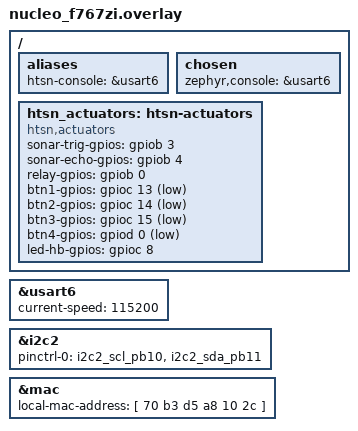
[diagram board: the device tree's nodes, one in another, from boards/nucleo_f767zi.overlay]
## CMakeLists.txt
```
# htsn-tsn endpoint (STM32 Nucleo-F767ZI) — Zephyr build.
#
# Replaces the previous STM32CubeIDE / FreeRTOS / lwIP CMake build (see git
# history). Build + flash with west (a Zephyr SDK is required; see README
# "Building & flashing"):
#
#   cd stm32-tsn
#   west build -b nucleo_f767zi .
#   west flash -r          # on-board ST-Link (or: west flash --runner openocd)
#
# The app's source tree is unchanged from the FreeRTOS build in *layout*; the
# C files use the Zephyr kernel / device model instead of FreeRTOS + STM32 HAL.
cmake_minimum_required(VERSION 3.20.0)

find_package(Zephyr REQUIRED HINTS $ENV{ZEPHYR_BASE})
project(htsn_tsn C ASM)

target_sources(app PRIVATE
  src/main.c
  Board/board.c
  Board/pwm.c
  tsn/ptp.c
  tsn/htsn_clock.c
  tsn/eth_proto.c
  actuators/htsn_sonar.c
  actuators/htsn_display.c
  actuators/htsn_actuator.c)

target_include_directories(app PRIVATE
  inc
  Board
  tsn
  actuators)
```

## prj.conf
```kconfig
# htsn-tsn endpoint (Zephyr) — Nucleo-F767ZI
CONFIG_COMPILER_OPT="-Os"

# ---- Threads ----
CONFIG_MAIN_STACK_SIZE=2048
CONFIG_SYSTEM_WORKQUEUE_STACK_SIZE=4096
CONFIG_INIT_STACKS=y
CONFIG_HEAP_MEM_POOL_SIZE=8192

# ---- Real-time preemption (gPTP timing) ----
# The Zephyr 4.5 kernel is fully preemptable by default (CONFIG_PREEMPT_ENABLED);
# there is no more CONFIG_PREEMPT symbol to set. Make the net I/O threads
# preemptive too, so an inbound Sync frame is handed to the socket (and the PTP
# thread's select() wakes) promptly, cutting T3 jitter. The RX thread runs at
# prio 2, the TX threads around prio 7; the PTP thread is raised to prio 4
# (tsn/ptp.c) so it sits above the TX/flow/cmd threads but below the RX thread
# and heartbeat.
CONFIG_NET_TC_THREAD_PREEMPTIVE=y
CONFIG_ETH_STM32_HAL_RX_THREAD_PREEMPTIVE=y

# ---- Console: printf (LOGI/LOGW/LOGE) -> USART6 (the NUCLEO ST-Link VCP) ----
CONFIG_SERIAL=y
CONFIG_CONSOLE=y
CONFIG_UART_CONSOLE=y
CONFIG_LOG=n

# ---- Networking: Zephyr net stack + POSIX sockets (replaces lwIP) ----
CONFIG_NETWORKING=y
CONFIG_POSIX_API=y
CONFIG_POSIX_NETWORKING=y
CONFIG_NET_IPV4=y
CONFIG_NET_IPV6=n
CONFIG_NET_SOCKETS=y
CONFIG_NET_UDP=y
CONFIG_NET_TCP=n
# IPv4 multicast (gPTP slave joins 224.0.1.129, see tsn/ptp.c) is enabled by
# CONFIG_NET_IPV4=y above; Zephyr 4.5 has no separate multicast Kconfig symbol.
# AF_PACKET raw socket: used to emit 802.1Q-tagged telemetry egress (VLAN/PCP)
# once a TSN config with vlan_id>0 is applied. See tsn/eth_proto.c.
CONFIG_NET_SOCKETS_PACKET=y
# IGMPv2: required for setsockopt(IP_ADD_MEMBERSHIP) in tsn/ptp.c to actually
# join the PTP multicast group (224.0.1.129). Without it net_ipv4_igmp_join is
# compiled out and the join returns -ENOSYS, so the IPv4 layer drops the GM's
# multicast Sync/Follow_Up and the clock never locks. Selects NET_IPV4_HDR_OPTIONS.
CONFIG_NET_IPV4_IGMP=y
# Promiscuous mode: the STM32 DWc MAC driver cannot program its hardware
# multicast filter (no ETHERNET_FILTER_TYPE_DST_MAC_ADDRESS), so even with a
# successful IGMP join the NIC would drop the 224.0.1.129 frames at L2. Promisc
# lets the NIC pass them to the stack; the IGMP join above then accepts them at
# L3 and the UDP socket receives the Sync/Follow_Up/Delay_Resp.
CONFIG_NET_PROMISCUOUS_MODE=y
CONFIG_NET_IPV4_AUTO=y
CONFIG_NET_CONFIG_INIT_TIMEOUT=10
CONFIG_NET_DEFAULT_IF_ETHERNET=y

# Static L3 config (no DHCP): the endpoint is 192.168.1.20, the RPi/CNC is
# 192.168.1.10. The PTP + UDP control/telemetry link both ride this.
CONFIG_NET_CONFIG_SETTINGS=y
CONFIG_NET_CONFIG_PEER_IPV4_ADDR="192.168.1.10"
CONFIG_NET_CONFIG_MY_IPV4_ADDR="192.168.1.20"
CONFIG_NET_CONFIG_MY_IPV4_NETMASK="255.255.255.0"
CONFIG_NET_DHCPV4=n

# ---- Ethernet: STM32 MAC + the on-board LAN8742A PHY ----
# (auto-selected from the &ethernet node in the overlay; the PHY comes from the
# board DTS. If your Zephyr version names the driver differently, set the
# matching symbol here — see README "First build".)
CONFIG_ETH_STM32_HAL=y
CONFIG_NET_ARP_TABLE_SIZE=4
CONFIG_NET_SHELL=n

# ---- Net buffers / connections ----
# Headroom for IPv4 multicast delivery (net_conn_input clones the datagram per
# matching socket) plus the PTP, command and tagged-egress sockets, and enable
# the STM32 HAL receive filter so the 224.0.1.129 group is accepted.
CONFIG_NET_BUF_RX_COUNT=96
CONFIG_NET_BUF_TX_COUNT=48
CONFIG_NET_PKT_RX_COUNT=32
CONFIG_NET_PKT_TX_COUNT=32
CONFIG_NET_MAX_CONN=16
CONFIG_NET_MAX_CONTEXTS=16
CONFIG_ETH_STM32_MULTICAST_FILTER=y
CONFIG_NET_L2_ETHERNET_MCAST_FILTER_COUNT=4

# ---- PWM: servo (SG90) + buzzer, driven by Board/pwm.c (CMSIS shim) ----
CONFIG_PWM=y

# ---- I2C: SSD1306 OLED ----
CONFIG_I2C=y

# ---- GPIO: sonar, relay, buttons, heartbeat LED ----
CONFIG_GPIO=y
```

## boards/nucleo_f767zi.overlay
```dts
/* htsn-tsn endpoint peripheral overlay — Nucleo-F767ZI (Zephyr).
 *
 * The board DTS (boards/st/nucleo_f7/nucleo_f767zi.dts) provides the base
 * (UART, I2C2, the Ethernet MAC + LAN8742A PHY, GPIO controllers, timers).
 * This overlay (1) points the console at USART6, (2) enables the I2C2 OLED
 * bus and the Ethernet MAC with the endpoint MAC, and (3) declares the
 * actuator pins — the single source of truth for the physical wiring.
 *
 * RESERVED (on-board LAN8742A PHY): PA1/PA2/PA7/PC1/PC4/PC5 — do not reuse.
 *
 * The servo (PA8/TIM1_CH1) and buzzer (PB1/TIM3_CH4) PWM outputs are NOT
 * declared here: they are programmed directly in Board/pwm.c (a CMSIS shim),
 * which keeps the port independent of the version-fragile STM32 PWM binding.
 */
#include <dt-bindings/gpio/gpio.h>

/ {
	aliases {
		htsn-console = &usart6;
	};
	chosen {
		zephyr,console = &usart6;
	};

	/* Logical actuator wiring. C code reads these via GPIO_DT_SPEC_GET(). */
	htsn_actuators: htsn-actuators {
		compatible = "htsn,actuators";

		/* HC-SR04 sonar */
		sonar-trig-gpios = <&gpiob 3 GPIO_ACTIVE_HIGH>;
		sonar-echo-gpios = <&gpiob 4 GPIO_ACTIVE_HIGH>;

		/* Relay (drive high to energise) */
		relay-gpios      = <&gpiob 0 GPIO_ACTIVE_HIGH>;

		/* 4 push-buttons (active low, internal pull-up) */
		btn1-gpios = <&gpioc 13 (GPIO_ACTIVE_LOW | GPIO_PULL_UP)>;
		btn2-gpios = <&gpioc 14 (GPIO_ACTIVE_LOW | GPIO_PULL_UP)>;
		btn3-gpios = <&gpioc 15 (GPIO_ACTIVE_LOW | GPIO_PULL_UP)>;
		btn4-gpios = <&gpiod 0  (GPIO_ACTIVE_LOW | GPIO_PULL_UP)>;

		/* On-board heartbeat LED (LD1, PC8) */
		led-hb-gpios   = <&gpioc 8 GPIO_ACTIVE_HIGH>;
	};
};

/* ---- console: USART6 at 115200 (ST-Link VCP) ---- */
&usart6 {
	status = "okay";
	current-speed = <115200>;
};

/* ---- I2C2: SSD1306 OLED (PB10/PB11) ---- */
&i2c2 {
	status = "okay";
	pinctrl-0 = <&i2c2_scl_pb10 &i2c2_sda_pb11>;
	pinctrl-names = "default";
};

/* ---- Ethernet MAC: the on-board LAN8742A (PHY handled by the board DTS) ---- */
&mac {
	status = "okay";
	local-mac-address = [ 70 b3 d5 a8 10 2c ];
};
```

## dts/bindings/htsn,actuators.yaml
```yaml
description: HTSN TSN endpoint actuator pins

compatible: "htsn,actuators"

properties:
  sonar-trig-gpios:
    type: phandle-array
    description: HC-SR04 sonar trigger pin

  sonar-echo-gpios:
    type: phandle-array
    description: HC-SR04 sonar echo pin

  relay-gpios:
    type: phandle-array
    description: Relay control pin

  btn1-gpios:
    type: phandle-array
    description: Button 1

  btn2-gpios:
    type: phandle-array
    description: Button 2

  btn3-gpios:
    type: phandle-array
    description: Button 3

  btn4-gpios:
    type: phandle-array
    description: Button 4

  led-hb-gpios:
    type: phandle-array
    description: Heartbeat LED
```

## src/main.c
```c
/* htsn-tsn endpoint application (STM32F767ZI) — Zephyr.
 *
 * The RPi (CNC) is the peer: it is the PTP v2 grandmaster (ptpd), TSN
 * controller, OPC UA server, MQTT broker and the GUI. The PC is NOT a runtime
 * node.
 *
 * Zephyr (device model + DT overlay) brings up clocks, the USART6 console,
 * I2C2 and the Ethernet MAC before main() runs. This file is the application
 * layer on top of that: it starts the actuator PWM, the transport, PTP, and
 * the display/heartbeat threads.
 */
#include <zephyr/kernel.h>
#include "stm32f7xx.h"

#include "htsn_config.h"
#include "htsn_port.h"
#include "htsn_net.h"
#include "ptp.h"
#include "board.h"
#include "pwm.h"
#include "htsn_sonar.h"
#include "htsn_display.h"
#include "htsn_actuator.h"

#include <string.h>
#include <stdlib.h>

/* Command handler: the RPi CNC sends short verbs over the TSN link. */
static void on_command(const char *cmd, const char *arg, void *ud)
{
	(void)ud;
	if (!cmd) return;
	if (strcmp(cmd, "servo") == 0)       htsn_sonar_set_angle(atoi(arg));
	else if (strcmp(cmd, "sonar") == 0)  htsn_sonar_trigger();
	else if (strcmp(cmd, "relay") == 0)  htsn_actuator_relay(atoi(arg));
	else if (strcmp(cmd, "beep") == 0)   htsn_actuator_beep(atoi(arg));
	else if (strcmp(cmd, "hud") == 0)    htsn_display_on_telemetry(arg);
	else if (strcmp(cmd, "reboot") == 0) htsn_reset();
	else LOGW("unknown command '%s'\n", cmd);
}

static void on_button(int n, void *ud)
{
	(void)ud;
	LOGI("button %d pressed\n", n);
	/* buttons publish their state via htsn_display_tick(); a press can also
	 * trigger a sonar sweep, matching the esp32-02 behaviour. */
	htsn_sonar_trigger();
}

/* ---- display + heartbeat threads (started from main after init) ---- */
K_THREAD_STACK_DEFINE(display_stack, 4096);
K_THREAD_STACK_DEFINE(heartbeat_stack, 1024);
static struct k_thread display_thread, heartbeat_thread;

static void display_task_fn(void *a, void *b, void *c)
{
	(void)a; (void)b; (void)c;
	for (;;) {
		htsn_display_tick();
		k_msleep(100);
	}
}

static void heartbeat_task_fn(void *a, void *b, void *c)
{
	(void)a; (void)b; (void)c;
	for (;;) {
		board_heartbeat_toggle();
		k_msleep(1000);
	}
}

int main(void)
{
	board_dwt_init();
	board_heartbeat_init();
	htsn_pwm_init();               /* servo + buzzer (CMSIS shim) */

	htsn_display_set_btn_cb(on_button, NULL);
	htsn_net_set_cmd_cb(on_command, NULL);
	if (htsn_net_init() != 0)
		LOGE("net init failed — is the Ethernet link to the RPi CNC up?\n");
	htsn_ptp_init();

	htsn_sonar_init(HTSN_NODE_ID);
	htsn_display_init(HTSN_NODE_ID);   /* blocks ~0.5 s probing the OLED */
	htsn_actuator_init(HTSN_NODE_ID);

	k_thread_create(&display_thread, display_stack, K_THREAD_STACK_SIZEOF(display_stack),
	                display_task_fn, NULL, NULL, NULL, 4, 0, K_NO_WAIT);
	k_thread_create(&heartbeat_thread, heartbeat_stack, K_THREAD_STACK_SIZEOF(heartbeat_stack),
	                heartbeat_task_fn, NULL, NULL, NULL, 3, 0, K_NO_WAIT);

	LOGI("htsn-tsn endpoint %s up (CNC = %s)\n", HTSN_NODE_ID, CNC_IP);
	return 0;   /* main thread done; the other threads keep running */
}
```

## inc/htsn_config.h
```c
/* htsn-tsn node configuration: identity, network endpoints, timings. */
#ifndef HTSN_CONFIG_H
#define HTSN_CONFIG_H

/* Node identity (shown in the GUI and in every telemetry frame). */
#ifndef HTSN_NODE_ID
#define HTSN_NODE_ID "stm32-tsn-01"
#endif

/* Default MAC (the two low bits can be set by PD2/PG2-to-GND bridges for
 * multiple endpoints on one network, mirroring the Sienda reference design). */
#define HTSN_MAC "70:B3:D5:A8:10:2C"

/* Deterministic UDP protocol endpoints (the RPi/CNC is the peer).
 * The STM32 listens on CMD_PORT for commands; it sends telemetry to the CNC's
 * TELEM_ADDR:TELEM_PORT. All control/telemetry frames are priority-tagged. */
#define CNC_IP           "192.168.1.10"   /* RPi CNC TSN NIC (edit to your net) */
#define CNC_TELEM_PORT   4001             /* where the STM32 sends telemetry */
#define STM32_CMD_PORT   4000             /* where the STM32 receives commands */
/* RPi CNC link-layer address, needed to build 802.1Q-tagged raw frames
 * (the AF_PACKET path bypasses ARP). Point-to-point wired link. */
#define CNC_MAC          "98:fe:54:03:fe:bb"
/* L3 address of the RPi's tagged (VLAN 100) interface, eth0.100. Tagged
 * egress targets this (not CNC_IP, which sits on the untagged eth0): Linux
 * won't deliver a packet for an address that arrived on a *different*
 * interface, so the tag rides the matching tagged IP. */
#define CNC_TAG_IP       "192.168.1.11"
/* Source address used in the hand-built tagged IPv4 header (the STM32 base IP). */
#define CNC_TAG_SRC_IP   "192.168.1.20"

/* 802.1Q priority for TSN control traffic (6 = highest, VO/AC_VO). */
#define TSN_PCP          6u
#define TSN_VID          0u

/* PTP (802.1AS) domain number. Must match the RPi grandmaster's ptpd.conf
 * (domainNumber). The RPi pushes its SyncConfigs domain to the endpoint at
 * runtime; this is the boot default so the slave works before the first push. */
#define HTSN_PTP_DOMAIN  50u

/* Servo timing (SG90). */
#define SERVO_FREQ_HZ    50u
#define SERVO_MIN_US     1000u            /* 0 deg */
#define SERVO_MAX_US     2000u            /* 180 deg */

/* Sonar sweep. */
#define SONAR_ECHO_TIMEOUT_US 40000L
#define SONAR_SWEEP_ANGLES    180         /* one step per degree */
#define SONAR_STEP_MS         35

/* Display refresh. */
#define DISPLAY_REFRESH_MS    10000       /* 10 s info-panel cadence */
#define DISPLAY_PUB_MS        2000        /* button-state publish cadence */

#endif /* HTSN_CONFIG_H */
```

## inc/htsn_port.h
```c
/* Thin porting layer so the (ESP32-derived) actuator code compiles on the
 * STM32 without sprinkling vendor calls everywhere. Implemented in Board/. */
#ifndef HTSN_PORT_H
#define HTSN_PORT_H

#include <stdint.h>
#include <stdbool.h>
#include <stdio.h>

/* Monotonic microsecond clock (DWT cycle counter). Same role as the ESP's
 * esp_timer_get_time(). */
uint64_t htsn_now_us(void);

/* Busy-wait microsecond delay (DWT spin). Used for the HC-SR04 TRIG pulse. */
void htsn_delay_us(uint32_t us);

/* Full system reset (same role as esp_restart()). */
void htsn_reset(void);

/* Minimal logging (console/UART). Tag + format + optional args. */
#define LOGI(...) printf("[I] " __VA_ARGS__)
#define LOGW(...) printf("[W] " __VA_ARGS__)
#define LOGE(...) printf("[E] " __VA_ARGS__)

#endif /* HTSN_PORT_H */
```

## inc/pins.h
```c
/* htsn-tsn pin map — Nucleo-F767ZI.
 *
 * SUPERSEDED: the physical wiring now lives in the Zephyr device-tree overlay
 *   boards/nucleo_f767zi.overlay  (node `htsn-actuators`)
 * which is the single source of truth (the C reads pins via GPIO_DT_SPEC_GET).
 * This file is kept only as a human-readable index of what is wired where.
 *
 *   servo (SG90, 50 Hz PWM)   PA8  = TIM1_CH1   (Board/pwm.c)
 *   sonar HC-SR04             PB3  TRIG (out)   PB4 ECHO (in)
 *   buzzer (PWM beep)         PB1  = TIM3_CH4   (Board/pwm.c)
 *   relay (digital out)       PB0
 *   OLED SSD1306 (I2C2)       PB10 SCL  PB11 SDA
 *   buttons (active-low)      PC13  PC14  PC15  PD0
 *   heartbeat LED (LD1)       PC8
 *
 * RESERVED (on-board LAN8742A PHY): PA1/PA2/PA7/PC1/PC4/PC5 — do not reuse.
 */
#ifndef HTSN_PINS_H
#define HTSN_PINS_H
#endif /* HTSN_PINS_H */
```

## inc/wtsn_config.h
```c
/* wtsn-tsn node configuration: identity, network endpoints, timings. */
#ifndef WTSN_CONFIG_H
#define WTSN_CONFIG_H

/* Node identity (shown in the GUI and in every telemetry frame). */
#ifndef WTSN_NODE_ID
#define WTSN_NODE_ID "stm32-tsn-01"
#endif

/* Default MAC (the two low bits can be set by PD2/PG2-to-GND bridges for
 * multiple endpoints on one network, mirroring the Sienda reference design). */
#define WTSN_MAC {0x70, 0xB3, 0xD5, 0xA8, 0x10, 0x2C}

/* Deterministic UDP protocol endpoints (the RPi/CNC is the peer).
 * The STM32 listens on CMD_PORT for commands; it sends telemetry to the CNC's
 * TELEM_ADDR:TELEM_PORT. All control/telemetry frames are priority-tagged. */
#define CNC_IP           "192.168.1.10"   /* RPi CNC TSN NIC (edit to your net) */
#define CNC_TELEM_PORT   4001             /* where the STM32 sends telemetry */
#define STM32_CMD_PORT   4000             /* where the STM32 receives commands */

/* 802.1Q priority for TSN control traffic (6 = highest, VO/AC_VO). */
#define TSN_PCP          6u
#define TSN_VID          0u

/* Servo timing (SG90). */
#define SERVO_FREQ_HZ    50u
#define SERVO_MIN_US     1000u            /* 0 deg */
#define SERVO_MAX_US     2000u            /* 180 deg */

/* Sonar sweep. */
#define SONAR_ECHO_TIMEOUT_US 40000L
#define SONAR_SWEEP_ANGLES    180         /* one step per degree */
#define SONAR_STEP_MS         35

/* Display refresh. */
#define DISPLAY_REFRESH_MS    10000       /* 10 s info-panel cadence */
#define DISPLAY_PUB_MS        2000        /* button-state publish cadence */

#endif /* WTSN_CONFIG_H */
```

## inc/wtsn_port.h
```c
/* Thin porting layer so the (ESP32-derived) actuator code compiles on the
 * STM32 without sprinkling vendor calls everywhere. Implemented in Board/. */
#ifndef WTSN_PORT_H
#define WTSN_PORT_H

#include <stdint.h>
#include <stdbool.h>
#include <stdio.h>

/* Monotonic microsecond clock (DWT cycle counter). Same role as the ESP's
 * esp_timer_get_time(). */
uint64_t wtsn_now_us(void);

/* Busy-wait microsecond delay (DWT spin). Used for the HC-SR04 TRIG pulse. */
void wtsn_delay_us(uint32_t us);

/* Full system reset (same role as esp_restart()). */
void wtsn_reset(void);

/* Minimal logging (console/UART). Tag + format + optional args. */
#define LOGI(...) printf("[I] " __VA_ARGS__)
#define LOGW(...) printf("[W] " __VA_ARGS__)
#define LOGE(...) printf("[E] " __VA_ARGS__)

#endif /* WTSN_PORT_H */
```
